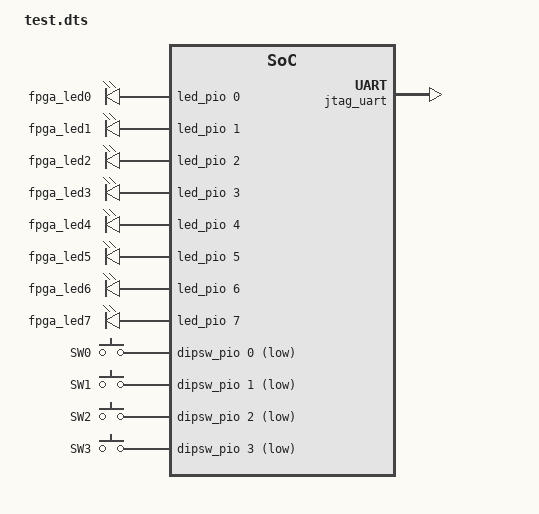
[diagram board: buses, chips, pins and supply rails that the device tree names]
/*
 * This devicetree is generated by sopc2dts version 20.1 [9b3346002ac555f36b80b1bc56dad1cb86298234] on Sun Dec 20 11:14:23 EST 2020
 * Sopc2dts is written by Walter Goossens <waltergoossens@home.nl>
 * in cooperation with the nios2 community <nios2-dev@lists.rocketboards.org>
 */

/ {
	clocks {
		#address-cells = <1>;
		#size-cells = <1>;

		clk_0: clk_0 {
			compatible = "fixed-clock";
			#clock-cells = <0>;
			clock-frequency = <50000000>;	/* 50.00 MHz */
			clock-output-names = "clk_0-clk";
		}; //end clk_0 (clk_0)
	}; //end clocks

	soc {
		ranges;
		compatible = "ALTR,avalon", "simple-bus";

		hps_0_bridges: bridge@0xc0000000 {
			compatible = "altr,bridge-20.1", "simple-bus";
			reg = <0xc0000000 0x20000000>,
				<0xff200000 0x00200000>;
			reg-names = "axi_h2f", "axi_h2f_lw";
			clocks = <&clk_0 &clk_0 &clk_0>;
			clock-names = "h2f_axi_clock", "h2f_lw_axi_clock", "f2h_sdram0_clock";
			#address-cells = <2>;
			#size-cells = <1>;
			ranges = <0x00000000 0x00000000 0xc0000000 0x00008000>,
				<0x00000001 0x00002000 0xff202000 0x00000008>,
				<0x00000001 0x00001000 0xff201000 0x00000008>,
				<0x00000001 0x00007000 0xff207000 0x00000008>,
				<0x00000001 0x00003000 0xff203000 0x00000010>,
				<0x00000001 0x00004000 0xff204000 0x00000010>,
				<0x00000001 0x00005000 0xff205000 0x00000010>;

			jtag_uart: serial@0x100002000 {
				compatible = "altr,juart-20.1", "altr,juart-1.0";
				reg = <0x00000001 0x00002000 0x00000008>;
				interrupt-parent = <&intc>;
				interrupts = <0 40 4>;
				clocks = <&clk_0>;
			}; //end serial@0x100002000 (jtag_uart)

			sysid_qsys: sysid@0x100001000 {
				compatible = "altr,sysid-20.1", "altr,sysid-1.0";
				reg = <0x00000001 0x00001000 0x00000008>;
				clocks = <&clk_0>;
				id = <2899645442>;	/* embeddedsw.dts.params.id type NUMBER */
				timestamp = <1608479571>;	/* embeddedsw.dts.params.timestamp type NUMBER */
			}; //end sysid@0x100001000 (sysid_qsys)

			chip_id_read_mm_0: unknown@0x100007000 {
				compatible = "unknown,unknown-1.0";
				reg = <0x00000001 0x00007000 0x00000008>;
				clocks = <&clk_0>;
			}; //end unknown@0x100007000 (chip_id_read_mm_0)

			led_pio: gpio@0x100003000 {
				compatible = "altr,pio-20.1", "altr,pio-1.0";
				reg = <0x00000001 0x00003000 0x00000010>;
				clocks = <&clk_0>;
				altr,gpio-bank-width = <8>;	/* embeddedsw.dts.params.altr,gpio-bank-width type NUMBER */
				resetvalue = <0>;	/* embeddedsw.dts.params.resetvalue type NUMBER */
				#gpio-cells = <2>;
				gpio-controller;
			}; //end gpio@0x100003000 (led_pio)

			dipsw_pio: gpio@0x100004000 {
				compatible = "altr,pio-20.1", "altr,pio-1.0";
				reg = <0x00000001 0x00004000 0x00000010>;
				interrupt-parent = <&intc>;
				interrupts = <0 41 1>;
				clocks = <&clk_0>;
				altr,gpio-bank-width = <4>;	/* embeddedsw.dts.params.altr,gpio-bank-width type NUMBER */
				altr,interrupt-type = <3>;	/* embeddedsw.dts.params.altr,interrupt-type type NUMBER */
				altr,interrupt_type = <3>;	/* embeddedsw.dts.params.altr,interrupt_type type NUMBER */
				edge_type = <2>;	/* embeddedsw.dts.params.edge_type type NUMBER */
				level_trigger = <0>;	/* embeddedsw.dts.params.level_trigger type NUMBER */
				resetvalue = <0>;	/* embeddedsw.dts.params.resetvalue type NUMBER */
				#gpio-cells = <2>;
				gpio-controller;
			}; //end gpio@0x100004000 (dipsw_pio)

			button_pio: gpio@0x100005000 {
				compatible = "altr,pio-20.1", "altr,pio-1.0";
				reg = <0x00000001 0x00005000 0x00000010>;
				interrupt-parent = <&intc>;
				interrupts = <0 42 1>;
				clocks = <&clk_0>;
				altr,gpio-bank-width = <2>;	/* embeddedsw.dts.params.altr,gpio-bank-width type NUMBER */
				altr,interrupt-type = <2>;	/* embeddedsw.dts.params.altr,interrupt-type type NUMBER */
				altr,interrupt_type = <2>;	/* embeddedsw.dts.params.altr,interrupt_type type NUMBER */
				edge_type = <1>;	/* embeddedsw.dts.params.edge_type type NUMBER */
				level_trigger = <0>;	/* embeddedsw.dts.params.level_trigger type NUMBER */
				resetvalue = <0>;	/* embeddedsw.dts.params.resetvalue type NUMBER */
				#gpio-cells = <2>;
				gpio-controller;
			}; //end gpio@0x100005000 (button_pio)
		}; //end bridge@0xc0000000 (hps_0_bridges)

		soc_leds: leds {
			compatible = "gpio-leds";	/* appended from boardinfo */

			led_fpga0: fpga0 {
				label = "fpga_led0";	/* appended from boardinfo */
				gpios = <&led_pio 0 0>;	/* appended from boardinfo */
			}; //end fpga0 (led_fpga0)

			led_fpga1: fpga1 {
				label = "fpga_led1";	/* appended from boardinfo */
				gpios = <&led_pio 1 0>;	/* appended from boardinfo */
			}; //end fpga1 (led_fpga1)

			led_fpga2: fpga2 {
				label = "fpga_led2";	/* appended from boardinfo */
				gpios = <&led_pio 2 0>;	/* appended from boardinfo */
			}; //end fpga2 (led_fpga2)

			led_fpga3: fpga3 {
				label = "fpga_led3";	/* appended from boardinfo */
				gpios = <&led_pio 3 0>;	/* appended from boardinfo */
			}; //end fpga3 (led_fpga3)

			led_fpga4: fpga4 {
				label = "fpga_led4";	/* appended from boardinfo */
				gpios = <&led_pio 4 0>;	/* appended from boardinfo */
			}; //end fpga4 (led_fpga4)

			led_fpga5: fpga5 {
				label = "fpga_led5";	/* appended from boardinfo */
				gpios = <&led_pio 5 0>;	/* appended from boardinfo */
			}; //end fpga5 (led_fpga5)

			led_fpga6: fpga6 {
				label = "fpga_led6";	/* appended from boardinfo */
				gpios = <&led_pio 6 0>;	/* appended from boardinfo */
			}; //end fpga6 (led_fpga6)

			led_fpga7: fpga7 {
				label = "fpga_led7";	/* appended from boardinfo */
				gpios = <&led_pio 7 0>;	/* appended from boardinfo */
			}; //end fpga7 (led_fpga7)
		}; //end leds (soc_leds)

		soc_keys: keys {
			compatible = "gpio-keys";	/* appended from boardinfo */
			#address-cells = <1>;	/* appended from boardinfo */
			#size-cells = <0>;	/* appended from boardinfo */

			SW0: SW0 {
				label = "SW0";	/* appended from boardinfo */
				gpios = <&dipsw_pio 0 1>;	/* appended from boardinfo */
				linux,code = <64>;	/* appended from boardinfo */
				debounce-interval = <50>;	/* appended from boardinfo */
			}; //end SW0 (SW0)

			SW1: SW1 {
				label = "SW1";	/* appended from boardinfo */
				gpios = <&dipsw_pio 1 1>;	/* appended from boardinfo */
				linux,code = <65>;	/* appended from boardinfo */
				debounce-interval = <50>;	/* appended from boardinfo */
			}; //end SW1 (SW1)

			SW2: SW2 {
				label = "SW2";	/* appended from boardinfo */
				gpios = <&dipsw_pio 2 1>;	/* appended from boardinfo */
				linux,code = <66>;	/* appended from boardinfo */
				debounce-interval = <50>;	/* appended from boardinfo */
			}; //end SW2 (SW2)

			SW3: SW3 {
				label = "SW3";	/* appended from boardinfo */
				gpios = <&dipsw_pio 3 1>;	/* appended from boardinfo */
				linux,code = <67>;	/* appended from boardinfo */
				debounce-interval = <50>;	/* appended from boardinfo */
			}; //end SW3 (SW3)
		}; //end keys (soc_keys)
	}; //end sopc@0 (sopc0)
}; //end /
